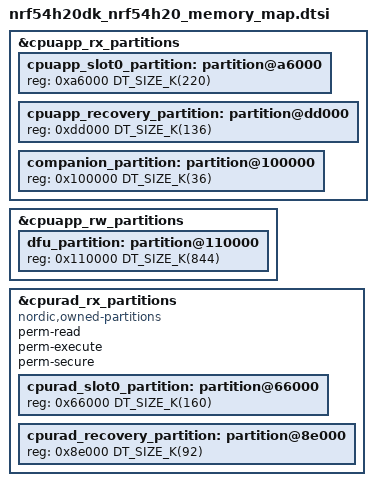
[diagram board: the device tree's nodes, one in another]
/*
 * Copyright (c) 2024 Nordic Semiconductor ASA
 *
 * SPDX-License-Identifier: LicenseRef-Nordic-5-Clause
 */

&cpuapp_rx_partitions {
	/delete-node/ partition@a6000;
	cpuapp_slot0_partition: partition@a6000 {
		reg = <0xa6000 DT_SIZE_K(220)>;
	};
	cpuapp_recovery_partition: partition@dd000 {
		reg = <0xdd000 DT_SIZE_K(136)>;
	};

	companion_partition: partition@100000 {
		reg = <0x100000 DT_SIZE_K(36)>;
	};
};

&cpuapp_rw_partitions {
	/delete-node/ partition@100000;
	dfu_partition: partition@110000 {
		reg = < 0x110000 DT_SIZE_K(844) >;
	};
};

&cpurad_rx_partitions {
	compatible = "nordic,owned-partitions", "fixed-partitions";
	status = "okay";
	perm-read;
	perm-execute;
	perm-secure;
	#address-cells = < 0x1 >;
	#size-cells = < 0x1 >;

	cpurad_slot0_partition: partition@66000 {
		reg = < 0x66000 DT_SIZE_K(160) >;
	};
	cpurad_recovery_partition: partition@8e000 {
		reg = < 0x8e000 DT_SIZE_K(92) >;
	};
};
